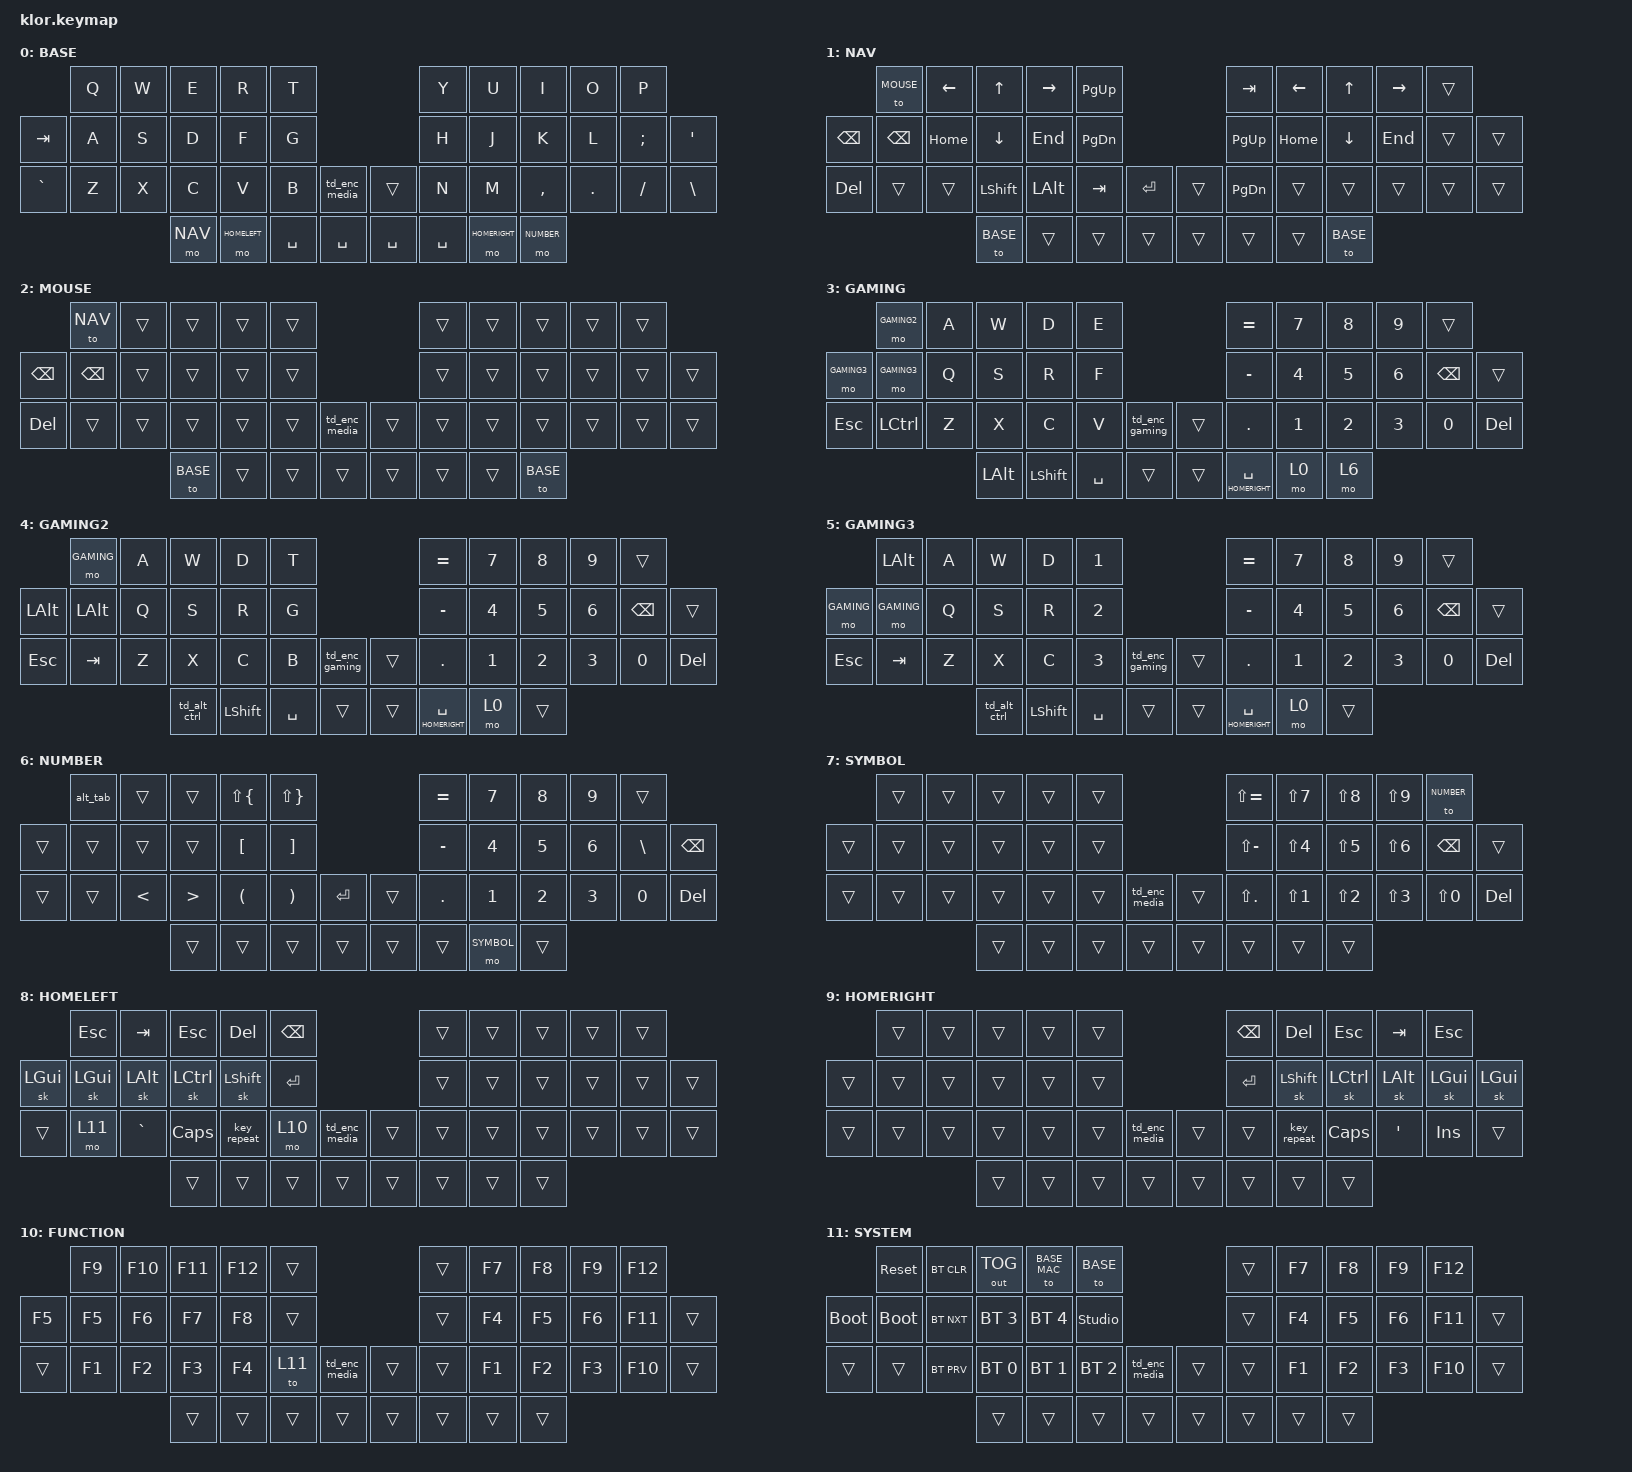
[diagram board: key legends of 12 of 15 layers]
//                               █         █    █            ▄▄▄▀▀▀▀▀▀▄▄▄        █▀▀▀▀▀▀▀▀▀▀█
//                               █        █     █          ▄▀            ▀▄      █          █
//                               █       █      █        ▄▀                ▀▄    █          █
//                               █      █       █        █                  █    █          █
//                               █     █        █       █                    █   █          █
//                               █    █         █       █                    █   █▄▄▄▄▄▄▄▄▄▄█
//                               █   █ █        █       █                    █   █      █
//                               █  █   █       █        █                  █    █       █
//                               █ █     █      █        ▀▄                ▄▀    █        █
//                               ██       █     █          ▀▄            ▄▀      █         █
//                               █         █    █▄▄▄▄▄▄▄▄    ▀▀▀▄▄▄▄▄▄▀▀▀        █          █
//
// ▄▄▄▄▄▄▄▄▄▄▄▄▄▄▄▄▄▄▄▄▄▄▄▄▄▄▄▄▄▄▄▄▄▄▄▄▄▄▄▄▄▄▄▄▄▄▄▄▄▄▄▄▄▄▄▄▄▄▄▄▄▄▄▄▄▄▄▄▄▄▄▄▄▄▄▄▄▄▄▄▄▄▄▄▄▄▄▄▄▄▄▄▄▄▄▄▄▄▄▄▄▄▄▄▄▄▄▄▄▄▄▄▄▄▄▄▄▄▄▄▄▄▄▄▄

#include <behaviors.dtsi>
#include <dt-bindings/zmk/bt.h>
#include <dt-bindings/zmk/keys.h>
#include <dt-bindings/zmk/outputs.h>

#define BASE   0
#define NAV    1
#define MOUSE  2
#define GAMING 3
#define GAMING2 4
#define GAMING3 5
#define NUMBER 6
#define SYMBOL 7
#define HOMELEFT 8
#define HOMERIGHT 9
#define FUNCTION 10
#define SYSTEM 11
#define BASE_MAC 12
#define HOMELEFT_MAC 13
#define HOMERIGHT_MAC 14
#define B0     BT_SEL 0
#define B1     BT_SEL 1
#define B2     BT_SEL 2
#define B3     BT_SEL 3
#define B4     BT_SEL 4
#define B5     BT_SEL 5
#define OTGL   out OUT_TOG
#define BT_C   BT_CLR
#define BT_C_A BT_CLR_ALL

/ {
    behaviors {
        // UNUSED as of the tap-dance layer fix -- retained so the change is easy to
        // revert. Wrapping &mo in a tap-dance made these layers unreachable; see
        // zmkfirmware/zmk#1691. Base now binds &mo NAV / &mo NUMBER directly.
        // Tap dance: single tap = NAV layer, double tap = MOUSE layer

        td_nav_mouse: td_nav_mouse {
            compatible = "zmk,behavior-tap-dance";
            #binding-cells = <0>;
            tapping-term-ms = <200>;
            bindings = <&mo NAV>, <&mo MOUSE>;
        };

        // Tap dance: single tap = NUMBER layer, double tap = SYMBOL layer

        td_num_sym: td_num_sym {
            compatible = "zmk,behavior-tap-dance";
            #binding-cells = <0>;
            tapping-term-ms = <200>;
            bindings = <&mo NUMBER>, <&mo SYMBOL>;
        };

        // Tap dance: single tap = play/pause, double tap = mute

        td_enc_media: td_enc_media {
            compatible = "zmk,behavior-tap-dance";
            #binding-cells = <0>;
            tapping-term-ms = <200>;
            bindings = <&kp C_PP>, <&kp C_MUTE>;
        };

        // Tap dance: single tap = F8, double tap = F7 (for gaming layer)

        td_enc_gaming: td_enc_gaming {
            compatible = "zmk,behavior-tap-dance";
            #binding-cells = <0>;
            tapping-term-ms = <200>;
            bindings = <&kp F8>, <&kp F7>;
        };

        td_alt_ctrl: td_alt_ctrl {
            compatible = "zmk,behavior-tap-dance";
            label = "TD_ALT_CTRL";
            #binding-cells = <0>;
            bindings = <&kp LEFT_ALT>, <&kp LCTRL>;
        };
    };

    combos {
        compatible = "zmk,combos";

        combo_esc {
            timeout-ms = <50>;
            key-positions = <1 0>;
            bindings = <&kp ESC>;
            layers = <8 9 13 14>;
        };

        reset_layers {
            bindings = <&to 0>;
            key-positions = <41 38>;
            require-prior-idle-ms = <100>;
        };

        quote {
            bindings = <&kp SQT>;
            key-positions = <19 20>;
            layers = <9>;
        };

        dash {
            bindings = <&kp MINUS>;
            key-positions = <31 32>;
            layers = <6>;
        };

        activate_gaming {
            bindings = <&to 3>;
            key-positions = <1 2 3 38>;
            layers = <0>;
        };

        tab {
            bindings = <&kp TAB>;
            key-positions = <11 12>;
            layers = <8>;
        };

        // Restricted to the &to-activated gaming layers. Positions 36/43 carry
        // layer behaviors on every other layer, and a key that belongs to a combo
        // has its press captured and withheld until the combo timeout expires
        // (combo.c: capture_pressed_key). Scoping the combo by layer means
        // setup_candidates_for_first_keypress() rejects it via combo_active_on_layer()
        // before any capture happens, so those keys resolve immediately on base.
        // Escaping other layers is already covered by reset_layers <41 38>.

        to-base {
            bindings = <&to 0>;
            key-positions = <36 43>;
            require-prior-idle-ms = <100>;
            layers = <3 4 5>;
        };

        escape {
            bindings = <&kp ESC>;
            key-positions = <23 11>;
            timeout-ms = <50>;
            layers = <3 4 5>;
        };

        map {
            bindings = <&kp M>;
            key-positions = <30 31>;
            layers = <3 4 5>;
        };

        inventory {
            bindings = <&kp I>;
            key-positions = <5 6>;
            layers = <3 4 5>;
        };

        gaming_reset_layers {
            bindings = <&to 0>;
            key-positions = <0 1 38>;
            layers = <3 4 5>;
        };

        esc {
            bindings = <&kp ESCAPE>;
            key-positions = <0 1>;
            layers = <3 4 5>;
        };

        gaming_tab {
            bindings = <&kp TAB>;
            key-positions = <11 12>;
            layers = <3 4 5>;
        };
    };

    macros {
        delete: delete {
            compatible = "zmk,behavior-macro";
            #binding-cells = <0>;
            bindings = <&macro_tap>, <&kp LS(BACKSPACE)>;

            label = "DELETE";
        };

        alt_tab: alt_tab {
            compatible = "zmk,behavior-macro";
            #binding-cells = <0>;
            bindings =
                <&macro_press>,
                <&kp LALT>,
                <&macro_tap>,
                <&kp TAB>,
                <&macro_release>,
                <&kp LALT>;

            label = "ALT_TAB";
        };
    };

    keymap {
        compatible = "zmk,keymap";

        // ▄▄▄▄▄▄▄▄▄▄▄▄▄▄▄▄▄▄▄▄▄▄▄▄▄▄▄▄▄▄▄▄▄▄▄▄▄▄▄▄▄▄▄▄▄▄▄▄▄▄▄▄▄▄▄▄▄▄▄▄▄▄▄▄▄▄▄▄▄▄▄▄▄▄▄▄▄▄▄▄▄▄▄▄▄▄▄▄▄▄▄▄▄▄▄▄▄▄▄▄▄▄▄▄▄▄▄▄▄▄▄▄▄▄▄▄▄▄▄▄▄▄▄▄▄▄▄▄▄▄▄▄▄▄▄▄▄▄▄▄▄▄

        base_layer {
            // ┌───────────────────────────────────────────────────────────┐

            label = "BASE";

            // └───────────────────────────────────────────────────────────┘

            bindings = <
           &kp Q  &kp W  &kp E    &kp R         &kp T                                &kp Y      &kp U          &kp I       &kp O    &kp P
&kp TAB    &kp A  &kp S  &kp D    &kp F         &kp G                                &kp H      &kp J          &kp K       &kp L    &kp SEMI  &kp SQT
&kp GRAVE  &kp Z  &kp X  &kp C    &kp V         &kp B      &td_enc_media  &trans     &kp N      &kp M          &kp COMMA   &kp DOT  &kp FSLH  &kp BSLH
                         &mo NAV  &mo HOMELEFT  &kp SPACE  &kp SPACE      &kp SPACE  &kp SPACE  &mo HOMERIGHT  &mo NUMBER
            >;

            sensor-bindings = <&inc_dec_kp C_VOL_UP C_VOL_DN>;
        };

        // ▄▄▄▄▄▄▄▄▄▄▄▄▄▄▄▄▄▄▄▄▄▄▄▄▄▄▄▄▄▄▄▄▄▄▄▄▄▄▄▄▄▄▄▄▄▄▄▄▄▄▄▄▄▄▄▄▄▄▄▄▄▄▄▄▄▄▄▄▄▄▄▄▄▄▄▄▄▄▄▄▄▄▄▄▄▄▄▄▄▄▄▄▄▄▄▄▄▄▄▄▄▄▄▄▄▄▄▄▄▄▄▄▄▄▄▄▄▄▄▄▄▄▄▄▄

        nav_layer {
            label = "NAV";
            bindings = <
          &to MOUSE  &kp LEFT  &kp UP     &kp RIGHT  &kp PG_UP                     &kp TAB    &kp LEFT  &kp UP    &kp RIGHT  &trans
&kp BSPC  &kp BSPC   &kp HOME  &kp DOWN   &kp END    &kp PG_DN                     &kp PG_UP  &kp HOME  &kp DOWN  &kp END    &trans  &trans
&kp DEL   &trans     &trans    &kp LSHFT  &kp LALT   &kp TAB    &kp ENTER  &trans  &kp PG_DN  &trans    &trans    &trans     &trans  &trans
                               &to BASE   &trans     &trans     &trans     &trans  &trans     &trans    &to BASE
            >;

            sensor-bindings = <&inc_dec_kp DOWN UP>;
        };

        // ▄▄▄▄▄▄▄▄▄▄▄▄▄▄▄▄▄▄▄▄▄▄▄▄▄▄▄▄▄▄▄▄▄▄▄▄▄▄▄▄▄▄▄▄▄▄▄▄▄▄▄▄▄▄▄▄▄▄▄▄▄▄▄▄▄▄▄▄▄▄▄▄▄▄▄▄▄▄▄▄▄▄▄▄▄▄▄▄▄▄▄▄▄▄▄▄▄▄▄▄▄▄▄▄▄▄▄▄▄▄▄▄▄▄▄▄▄▄▄▄▄▄▄▄▄

        mouse_layer {
            label = "MOUSE";
            bindings = <
          &to NAV   &trans  &trans    &trans  &trans                         &trans  &trans  &trans    &trans  &trans
&kp BSPC  &kp BSPC  &trans  &trans    &trans  &trans                         &trans  &trans  &trans    &trans  &trans  &trans
&kp DEL   &trans    &trans  &trans    &trans  &trans  &td_enc_media  &trans  &trans  &trans  &trans    &trans  &trans  &trans
                            &to BASE  &trans  &trans  &trans         &trans  &trans  &trans  &to BASE
            >;

            sensor-bindings = <&inc_dec_kp C_VOL_UP C_VOL_DN>;
        };

        // ▄▄▄▄▄▄▄▄▄▄▄▄▄▄▄▄▄▄▄▄▄▄▄▄▄▄▄▄▄▄▄▄▄▄▄▄▄▄▄▄▄▄▄▄▄▄▄▄▄▄▄▄▄▄▄▄▄▄▄▄▄▄▄▄▄▄▄▄▄▄▄▄▄▄▄▄▄▄▄▄▄▄▄▄▄▄▄▄▄▄▄▄▄▄▄▄▄▄▄▄▄▄▄▄▄▄▄▄▄▄▄▄▄▄▄▄▄▄▄▄▄▄▄▄▄

        gaming_layer {
            label = "GAMING";
            bindings = <
             &mo GAMING2  &kp A  &kp W         &kp D      &kp E                              &kp EQUAL            &kp N7  &kp N8  &kp N9  &trans
&mo GAMING3  &mo GAMING3  &kp Q  &kp S         &kp R      &kp F                              &kp MINUS            &kp N4  &kp N5  &kp N6  &kp BSPC  &trans
&kp ESC      &kp LCTRL    &kp Z  &kp X         &kp C      &kp V      &td_enc_gaming  &trans  &kp DOT              &kp N1  &kp N2  &kp N3  &kp N0    &kp DEL
                                 &kp LEFT_ALT  &kp LSHFT  &kp SPACE  &trans          &trans  &lt HOMERIGHT SPACE  &mo 0   &mo 6
            >;

            sensor-bindings = <&inc_dec_kp C_VOL_UP C_VOL_DN>;
        };

        // ▄▄▄▄▄▄▄▄▄▄▄▄▄▄▄▄▄▄▄▄▄▄▄▄▄▄▄▄▄▄▄▄▄▄▄▄▄▄▄▄▄▄▄▄▄▄▄▄▄▄▄▄▄▄▄▄▄▄▄▄▄▄▄▄▄▄▄▄▄▄▄▄▄▄▄▄▄▄▄▄▄▄▄▄▄▄▄▄▄▄▄▄▄▄▄▄▄▄▄▄▄▄▄▄▄▄▄▄▄▄▄▄▄▄▄▄▄▄▄▄▄▄▄▄▄

        gaming2_layer {
            label = "GAMING2";
            bindings = <
          &mo GAMING  &kp A  &kp W         &kp D      &kp T                              &kp EQUAL            &kp N7  &kp N8  &kp N9  &trans
&kp LALT  &kp LALT    &kp Q  &kp S         &kp R      &kp G                              &kp MINUS            &kp N4  &kp N5  &kp N6  &kp BSPC  &trans
&kp ESC   &kp TAB     &kp Z  &kp X         &kp C      &kp B      &td_enc_gaming  &trans  &kp DOT              &kp N1  &kp N2  &kp N3  &kp N0    &kp DEL
                             &td_alt_ctrl  &kp LSHFT  &kp SPACE  &trans          &trans  &lt HOMERIGHT SPACE  &mo 0   &trans
            >;

            sensor-bindings = <&inc_dec_kp C_VOL_UP C_VOL_DN>;
        };

        // ▄▄▄▄▄▄▄▄▄▄▄▄▄▄▄▄▄▄▄▄▄▄▄▄▄▄▄▄▄▄▄▄▄▄▄▄▄▄▄▄▄▄▄▄▄▄▄▄▄▄▄▄▄▄▄▄▄▄▄▄▄▄▄▄▄▄▄▄▄▄▄▄▄▄▄▄▄▄▄▄▄▄▄▄▄▄▄▄▄▄▄▄▄▄▄▄▄▄▄▄▄▄▄▄▄▄▄▄▄▄▄▄▄▄▄▄▄▄▄▄▄▄▄▄▄

        gaming3_layer {
            label = "GAMING3";
            bindings = <
            &kp LALT    &kp A  &kp W         &kp D      &kp N1                             &kp EQUAL            &kp N7  &kp N8  &kp N9  &trans
&mo GAMING  &mo GAMING  &kp Q  &kp S         &kp R      &kp N2                             &kp MINUS            &kp N4  &kp N5  &kp N6  &kp BSPC  &trans
&kp ESC     &kp TAB     &kp Z  &kp X         &kp C      &kp N3     &td_enc_gaming  &trans  &kp DOT              &kp N1  &kp N2  &kp N3  &kp N0    &kp DEL
                               &td_alt_ctrl  &kp LSHFT  &kp SPACE  &trans          &trans  &lt HOMERIGHT SPACE  &mo 0   &trans
            >;

            sensor-bindings = <&inc_dec_kp C_VOL_UP C_VOL_DN>;
        };

        // ▄▄▄▄▄▄▄▄▄▄▄▄▄▄▄▄▄▄▄▄▄▄▄▄▄▄▄▄▄▄▄▄▄▄▄▄▄▄▄▄▄▄▄▄▄▄▄▄▄▄▄▄▄▄▄▄▄▄▄▄▄▄▄▄▄▄▄▄▄▄▄▄▄▄▄▄▄▄▄▄▄▄▄▄▄▄▄▄▄▄▄▄▄▄▄▄▄▄▄▄▄▄▄▄▄▄▄▄▄▄▄▄▄▄▄▄▄▄▄▄▄▄▄▄▄

        number_layer {
            label = "NUMBER";
            bindings = <
        &alt_tab  &trans         &trans            &kp LS(LBRC)  &kp LS(RBRC)                     &kp EQUAL  &kp N7      &kp N8  &kp N9  &trans
&trans  &trans    &trans         &trans            &kp LBKT      &kp RBKT                         &kp MINUS  &kp N4      &kp N5  &kp N6  &kp BACKSLASH  &kp BACKSPACE
&trans  &trans    &kp LESS_THAN  &kp GREATER_THAN  &kp LPAR      &kp RPAR      &kp ENTER  &trans  &kp DOT    &kp N1      &kp N2  &kp N3  &kp N0         &kp DEL
                                 &trans            &trans        &trans        &trans     &trans  &trans     &mo SYMBOL  &trans
            >;

            sensor-bindings = <&inc_dec_kp RIGHT LEFT>;
        };

        // ▄▄▄▄▄▄▄▄▄▄▄▄▄▄▄▄▄▄▄▄▄▄▄▄▄▄▄▄▄▄▄▄▄▄▄▄▄▄▄▄▄▄▄▄▄▄▄▄▄▄▄▄▄▄▄▄▄▄▄▄▄▄▄▄▄▄▄▄▄▄▄▄▄▄▄▄▄▄▄▄▄▄▄▄▄▄▄▄▄▄▄▄▄▄▄▄▄▄▄▄▄▄▄▄▄▄▄▄▄▄▄▄▄▄▄▄▄▄▄▄▄▄▄▄▄

        symbol_layer {
            label = "SYMBOL";
            bindings = <
        &trans  &trans  &trans  &trans  &trans                         &kp LS(EQUAL)  &kp LS(N7)  &kp LS(N8)  &kp LS(N9)  &to NUMBER
&trans  &trans  &trans  &trans  &trans  &trans                         &kp LS(MINUS)  &kp LS(N4)  &kp LS(N5)  &kp LS(N6)  &kp BSPC    &trans
&trans  &trans  &trans  &trans  &trans  &trans  &td_enc_media  &trans  &kp LS(DOT)    &kp LS(N1)  &kp LS(N2)  &kp LS(N3)  &kp LS(N0)  &kp DEL
                        &trans  &trans  &trans  &trans         &trans  &trans         &trans      &trans
            >;

            sensor-bindings = <&inc_dec_kp RIGHT LEFT>;
        };

        // ▄▄▄▄▄▄▄▄▄▄▄▄▄▄▄▄▄▄▄▄▄▄▄▄▄▄▄▄▄▄▄▄▄▄▄▄▄▄▄▄▄▄▄▄▄▄▄▄▄▄▄▄▄▄▄▄▄▄▄▄▄▄▄▄▄▄▄▄▄▄▄▄▄▄▄▄▄▄▄▄▄▄▄▄▄▄▄▄▄▄▄▄▄▄▄▄▄▄▄▄▄▄▄▄▄▄▄▄▄▄▄▄▄▄▄▄▄▄▄▄▄▄▄▄▄

        homeleft_layer {
            label = "HOMELEFT";
            bindings = <
          &kp ESC   &kp TAB    &kp ESC       &kp DEL      &kp BSPC                         &trans  &trans  &trans  &trans  &trans
&sk LGUI  &sk LGUI  &sk LALT   &sk LCTRL     &sk LSHFT    &kp RET                          &trans  &trans  &trans  &trans  &trans  &trans
&trans    &mo 11    &kp GRAVE  &kp CAPSLOCK  &key_repeat  &mo 10    &td_enc_media  &trans  &trans  &trans  &trans  &trans  &trans  &trans
                               &trans        &trans       &trans    &trans         &trans  &trans  &trans  &trans
            >;

            sensor-bindings = <&inc_dec_kp C_VOL_UP C_VOL_DN>;
        };

        // ▄▄▄▄▄▄▄▄▄▄▄▄▄▄▄▄▄▄▄▄▄▄▄▄▄▄▄▄▄▄▄▄▄▄▄▄▄▄▄▄▄▄▄▄▄▄▄▄▄▄▄▄▄▄▄▄▄▄▄▄▄▄▄▄▄▄▄▄▄▄▄▄▄▄▄▄▄▄▄▄▄▄▄▄▄▄▄▄▄▄▄▄▄▄▄▄▄▄▄▄▄▄▄▄▄▄▄▄▄▄▄▄▄▄▄▄▄▄▄▄▄▄▄▄▄

        homeright_layer {
            label = "HOMERIGHT";
            bindings = <
        &trans  &trans  &trans  &trans  &trans                         &kp BSPC  &kp DEL      &kp ESC       &kp TAB   &kp ESC
&trans  &trans  &trans  &trans  &trans  &trans                         &kp RET   &sk LSHFT    &sk LCTRL     &sk LALT  &sk LGUI    &sk LGUI
&trans  &trans  &trans  &trans  &trans  &trans  &td_enc_media  &trans  &trans    &key_repeat  &kp CAPSLOCK  &kp SQT   &kp INSERT  &trans
                        &trans  &trans  &trans  &trans         &trans  &trans    &trans       &trans
            >;

            sensor-bindings = <&inc_dec_kp C_VOL_UP C_VOL_DN>;
        };

        // ▄▄▄▄▄▄▄▄▄▄▄▄▄▄▄▄▄▄▄▄▄▄▄▄▄▄▄▄▄▄▄▄▄▄▄▄▄▄▄▄▄▄▄▄▄▄▄▄▄▄▄▄▄▄▄▄▄▄▄▄▄▄▄▄▄▄▄▄▄▄▄▄▄▄▄▄▄▄▄▄▄▄▄▄▄▄▄▄▄▄▄▄▄▄▄▄▄▄▄▄▄▄▄▄▄▄▄▄▄▄▄▄▄▄▄▄▄▄▄▄▄▄▄▄▄

        function_layer {
            label = "FUNCTION";
            bindings = <
        &kp F9  &kp F10  &kp F11  &kp F12  &trans                         &trans  &kp F7  &kp F8  &kp F9  &kp F12
&kp F5  &kp F5  &kp F6   &kp F7   &kp F8   &trans                         &trans  &kp F4  &kp F5  &kp F6  &kp F11  &trans
&trans  &kp F1  &kp F2   &kp F3   &kp F4   &to 11  &td_enc_media  &trans  &trans  &kp F1  &kp F2  &kp F3  &kp F10  &trans
                         &trans   &trans   &trans  &trans         &trans  &trans  &trans  &trans
            >;

            sensor-bindings = <&inc_dec_kp C_VOL_UP C_VOL_DN>;
        };

        // ▄▄▄▄▄▄▄▄▄▄▄▄▄▄▄▄▄▄▄▄▄▄▄▄▄▄▄▄▄▄▄▄▄▄▄▄▄▄▄▄▄▄▄▄▄▄▄▄▄▄▄▄▄▄▄▄▄▄▄▄▄▄▄▄▄▄▄▄▄▄▄▄▄▄▄▄▄▄▄▄▄▄▄▄▄▄▄▄▄▄▄▄▄▄▄▄▄▄▄▄▄▄▄▄▄▄▄▄▄▄▄▄▄▄▄▄▄▄▄▄▄▄▄▄▄

        system_layer {
            label = "SYSTEM";
            bindings = <
             &sys_reset   &bt BT_CLR  &out OUT_TOG  &to BASE_MAC  &to BASE                               &trans  &kp F7  &kp F8  &kp F9  &kp F12
&bootloader  &bootloader  &bt BT_NXT  &bt BT_SEL 3  &bt BT_SEL 4  &studio_unlock                         &trans  &kp F4  &kp F5  &kp F6  &kp F11  &trans
&trans       &trans       &bt BT_PRV  &bt BT_SEL 0  &bt BT_SEL 1  &bt BT_SEL 2    &td_enc_media  &trans  &trans  &kp F1  &kp F2  &kp F3  &kp F10  &trans
                                      &trans        &trans        &trans          &trans         &trans  &trans  &trans  &trans
            >;

            sensor-bindings = <&inc_dec_kp C_VOL_UP C_VOL_DN>;
        };

        // ▄▄▄▄▄▄▄▄▄▄▄▄▄▄▄▄▄▄▄▄▄▄▄▄▄▄▄▄▄▄▄▄▄▄▄▄▄▄▄▄▄▄▄▄▄▄▄▄▄▄▄▄▄▄▄▄▄▄▄▄▄▄▄▄▄▄▄▄▄▄▄▄▄▄▄▄▄▄▄▄▄▄▄▄▄▄▄▄▄▄▄▄▄▄▄▄▄▄▄▄▄▄▄▄▄▄▄▄▄▄▄▄▄▄▄▄▄▄▄▄▄▄▄▄▄

        base_mac_layer {
            label = "BASE_MAC";
            bindings = <
        &kp Q     &kp W  &kp E    &kp R             &kp T                              &kp Y      &kp U              &kp I       &kp O    &kp P
&trans  &kp A     &kp S  &kp D    &kp F             &kp G                              &kp H      &kp J              &kp K       &kp L    &kp SEMI  &kp SQT
&trans  &lt 11 Z  &kp X  &kp C    &kp V             &lt 10 B   &td_enc_media  &trans   &kp N      &kp M              &kp COMMA   &kp DOT  &kp FSLH  &kp BSLH
                         &mo NAV  &mo HOMELEFT_MAC  &kp SPACE  &kp DEL        &kp TAB  &kp SPACE  &mo HOMERIGHT_MAC  &mo NUMBER
            >;

            sensor-bindings = <&inc_dec_kp C_VOL_UP C_VOL_DN>;
        };

        // ▄▄▄▄▄▄▄▄▄▄▄▄▄▄▄▄▄▄▄▄▄▄▄▄▄▄▄▄▄▄▄▄▄▄▄▄▄▄▄▄▄▄▄▄▄▄▄▄▄▄▄▄▄▄▄▄▄▄▄▄▄▄▄▄▄▄▄▄▄▄▄▄▄▄▄▄▄▄▄▄▄▄▄▄▄▄▄▄▄▄▄▄▄▄▄▄▄▄▄▄▄▄▄▄▄▄▄▄▄▄▄▄▄▄▄▄▄▄▄▄▄▄▄▄▄

        homeleft_mac_layer {
            label = "HOMELEFT_MAC";
            bindings = <
           &key_repeat  &kp TAB   &kp ESC   &kp DEL    &kp BSPC                         &trans  &trans  &trans  &trans  &trans
&sk LCTRL  &sk LCTRL    &sk LALT  &sk LGUI  &sk LSHFT  &kp RET                          &trans  &trans  &trans  &trans  &trans  &trans
&trans     &trans       &trans    &trans    &trans     &trans    &td_enc_media  &trans  &trans  &trans  &trans  &trans  &trans  &trans
                                  &trans    &trans     &trans    &trans         &trans  &trans  &trans  &trans
            >;

            sensor-bindings = <&inc_dec_kp C_VOL_UP C_VOL_DN>;
        };

        // ▄▄▄▄▄▄▄▄▄▄▄▄▄▄▄▄▄▄▄▄▄▄▄▄▄▄▄▄▄▄▄▄▄▄▄▄▄▄▄▄▄▄▄▄▄▄▄▄▄▄▄▄▄▄▄▄▄▄▄▄▄▄▄▄▄▄▄▄▄▄▄▄▄▄▄▄▄▄▄▄▄▄▄▄▄▄▄▄▄▄▄▄▄▄▄▄▄▄▄▄▄▄▄▄▄▄▄▄▄▄▄▄▄▄▄▄▄▄▄▄▄▄▄▄▄

        homeright_mac_layer {
            label = "HOMERIGHT_MAC";
            bindings = <
        &trans  &trans  &trans  &trans  &trans                         &kp BSPC  &kp DEL    &kp ESC   &kp TAB   &key_repeat
&trans  &trans  &trans  &trans  &trans  &trans                         &kp RET   &sk LSHFT  &sk LGUI  &sk LALT  &sk LCTRL    &sk LCTRL
&trans  &trans  &trans  &trans  &trans  &trans  &td_enc_media  &trans  &trans    &trans     &trans    &trans    &trans       &trans
                        &trans  &trans  &trans  &trans         &trans  &trans    &trans     &trans
            >;

            sensor-bindings = <&inc_dec_kp C_VOL_UP C_VOL_DN>;
        };
    };
};
